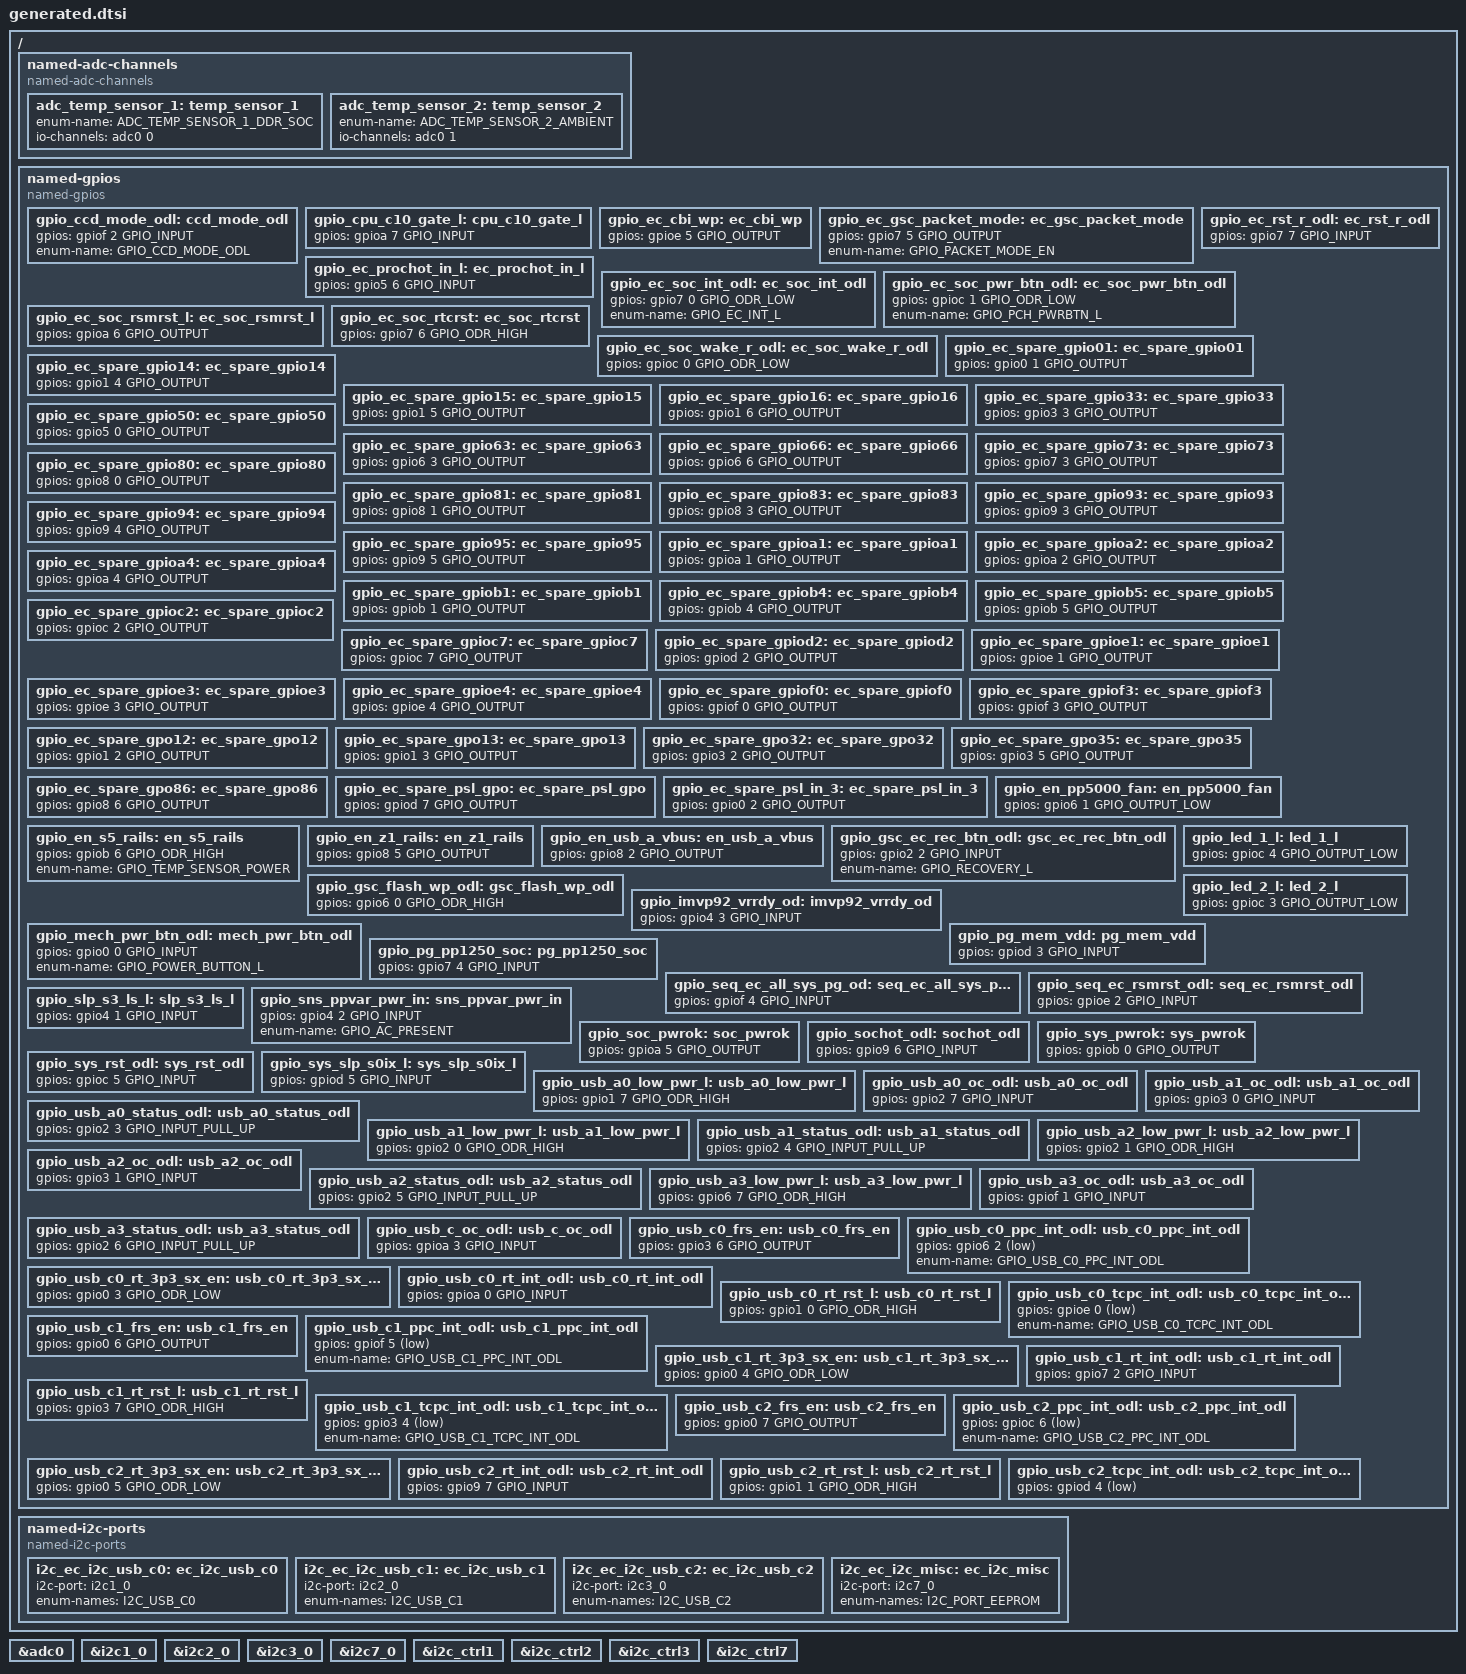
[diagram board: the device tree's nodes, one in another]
/* Copyright 2023 The ChromiumOS Authors
 * Use of this source code is governed by a BSD-style license that can be
 * found in the LICENSE file.
 *
 */

/ {

	named-adc-channels {
		compatible = "named-adc-channels";

		adc_temp_sensor_1: temp_sensor_1 {
			enum-name = "ADC_TEMP_SENSOR_1_DDR_SOC";
			io-channels = <&adc0 0>;
		};
		adc_temp_sensor_2: temp_sensor_2 {
			enum-name = "ADC_TEMP_SENSOR_2_AMBIENT";
			io-channels = <&adc0 1>;
		};
	};

	named-gpios {
		compatible = "named-gpios";

		gpio_ccd_mode_odl: ccd_mode_odl {
			gpios = <&gpiof 2 GPIO_INPUT>;
			enum-name = "GPIO_CCD_MODE_ODL";
		};
		gpio_cpu_c10_gate_l: cpu_c10_gate_l {
			gpios = <&gpioa 7 GPIO_INPUT>;
		};
		gpio_ec_cbi_wp: ec_cbi_wp {
			gpios = <&gpioe 5 GPIO_OUTPUT>;
		};
		gpio_ec_gsc_packet_mode: ec_gsc_packet_mode {
			gpios = <&gpio7 5 GPIO_OUTPUT>;
			enum-name = "GPIO_PACKET_MODE_EN";
		};
		gpio_ec_prochot_in_l: ec_prochot_in_l {
			gpios = <&gpio5 6 GPIO_INPUT>;
		};
		gpio_ec_rst_r_odl: ec_rst_r_odl {
			gpios = <&gpio7 7 GPIO_INPUT>;
		};
		gpio_ec_soc_int_odl: ec_soc_int_odl {
			gpios = <&gpio7 0 GPIO_ODR_LOW>;
			enum-name = "GPIO_EC_INT_L";
		};
		gpio_ec_soc_pwr_btn_odl: ec_soc_pwr_btn_odl {
			gpios = <&gpioc 1 GPIO_ODR_LOW>;
			enum-name = "GPIO_PCH_PWRBTN_L";
		};
		gpio_ec_soc_rsmrst_l: ec_soc_rsmrst_l {
			gpios = <&gpioa 6 GPIO_OUTPUT>;
		};
		gpio_ec_soc_rtcrst: ec_soc_rtcrst {
			gpios = <&gpio7 6 GPIO_ODR_HIGH>;
		};
		gpio_ec_soc_wake_r_odl: ec_soc_wake_r_odl {
			gpios = <&gpioc 0 GPIO_ODR_LOW>;
		};
		gpio_ec_spare_gpio01: ec_spare_gpio01 {
			gpios = <&gpio0 1 GPIO_OUTPUT>;
		};
		gpio_ec_spare_gpio14: ec_spare_gpio14 {
			gpios = <&gpio1 4 GPIO_OUTPUT>;
		};
		gpio_ec_spare_gpio15: ec_spare_gpio15 {
			gpios = <&gpio1 5 GPIO_OUTPUT>;
		};
		gpio_ec_spare_gpio16: ec_spare_gpio16 {
			gpios = <&gpio1 6 GPIO_OUTPUT>;
		};
		gpio_ec_spare_gpio33: ec_spare_gpio33 {
			gpios = <&gpio3 3 GPIO_OUTPUT>;
		};
		gpio_ec_spare_gpio50: ec_spare_gpio50 {
			gpios = <&gpio5 0 GPIO_OUTPUT>;
		};
		gpio_ec_spare_gpio63: ec_spare_gpio63 {
			gpios = <&gpio6 3 GPIO_OUTPUT>;
		};
		gpio_ec_spare_gpio66: ec_spare_gpio66 {
			gpios = <&gpio6 6 GPIO_OUTPUT>;
		};
		gpio_ec_spare_gpio73: ec_spare_gpio73 {
			gpios = <&gpio7 3 GPIO_OUTPUT>;
		};
		gpio_ec_spare_gpio80: ec_spare_gpio80 {
			gpios = <&gpio8 0 GPIO_OUTPUT>;
		};
		gpio_ec_spare_gpio81: ec_spare_gpio81 {
			gpios = <&gpio8 1 GPIO_OUTPUT>;
		};
		gpio_ec_spare_gpio83: ec_spare_gpio83 {
			gpios = <&gpio8 3 GPIO_OUTPUT>;
		};
		gpio_ec_spare_gpio93: ec_spare_gpio93 {
			gpios = <&gpio9 3 GPIO_OUTPUT>;
		};
		gpio_ec_spare_gpio94: ec_spare_gpio94 {
			gpios = <&gpio9 4 GPIO_OUTPUT>;
		};
		gpio_ec_spare_gpio95: ec_spare_gpio95 {
			gpios = <&gpio9 5 GPIO_OUTPUT>;
		};
		gpio_ec_spare_gpioa1: ec_spare_gpioa1 {
			gpios = <&gpioa 1 GPIO_OUTPUT>;
		};
		gpio_ec_spare_gpioa2: ec_spare_gpioa2 {
			gpios = <&gpioa 2 GPIO_OUTPUT>;
		};
		gpio_ec_spare_gpioa4: ec_spare_gpioa4 {
			gpios = <&gpioa 4 GPIO_OUTPUT>;
		};
		gpio_ec_spare_gpiob1: ec_spare_gpiob1 {
			gpios = <&gpiob 1 GPIO_OUTPUT>;
		};
		gpio_ec_spare_gpiob4: ec_spare_gpiob4 {
			gpios = <&gpiob 4 GPIO_OUTPUT>;
		};
		gpio_ec_spare_gpiob5: ec_spare_gpiob5 {
			gpios = <&gpiob 5 GPIO_OUTPUT>;
		};
		gpio_ec_spare_gpioc2: ec_spare_gpioc2 {
			gpios = <&gpioc 2 GPIO_OUTPUT>;
		};
		gpio_ec_spare_gpioc7: ec_spare_gpioc7 {
			gpios = <&gpioc 7 GPIO_OUTPUT>;
		};
		gpio_ec_spare_gpiod2: ec_spare_gpiod2 {
			gpios = <&gpiod 2 GPIO_OUTPUT>;
		};
		gpio_ec_spare_gpioe1: ec_spare_gpioe1 {
			gpios = <&gpioe 1 GPIO_OUTPUT>;
		};
		gpio_ec_spare_gpioe3: ec_spare_gpioe3 {
			gpios = <&gpioe 3 GPIO_OUTPUT>;
		};
		gpio_ec_spare_gpioe4: ec_spare_gpioe4 {
			gpios = <&gpioe 4 GPIO_OUTPUT>;
		};
		gpio_ec_spare_gpiof0: ec_spare_gpiof0 {
			gpios = <&gpiof 0 GPIO_OUTPUT>;
		};
		gpio_ec_spare_gpiof3: ec_spare_gpiof3 {
			gpios = <&gpiof 3 GPIO_OUTPUT>;
		};
		gpio_ec_spare_gpo12: ec_spare_gpo12 {
			gpios = <&gpio1 2 GPIO_OUTPUT>;
		};
		gpio_ec_spare_gpo13: ec_spare_gpo13 {
			gpios = <&gpio1 3 GPIO_OUTPUT>;
		};
		gpio_ec_spare_gpo32: ec_spare_gpo32 {
			gpios = <&gpio3 2 GPIO_OUTPUT>;
		};
		gpio_ec_spare_gpo35: ec_spare_gpo35 {
			gpios = <&gpio3 5 GPIO_OUTPUT>;
		};
		gpio_ec_spare_gpo86: ec_spare_gpo86 {
			gpios = <&gpio8 6 GPIO_OUTPUT>;
		};
		gpio_ec_spare_psl_gpo: ec_spare_psl_gpo {
			gpios = <&gpiod 7 GPIO_OUTPUT>;
		};
		gpio_ec_spare_psl_in_3: ec_spare_psl_in_3 {
			gpios = <&gpio0 2 GPIO_OUTPUT>;
		};
		gpio_en_pp5000_fan: en_pp5000_fan {
			gpios = <&gpio6 1 GPIO_OUTPUT_LOW>;
		};
		gpio_en_s5_rails: en_s5_rails {
			gpios = <&gpiob 6 GPIO_ODR_HIGH>;
			enum-name = "GPIO_TEMP_SENSOR_POWER";
		};
		gpio_en_z1_rails: en_z1_rails {
			gpios = <&gpio8 5 GPIO_OUTPUT>;
		};
		gpio_en_usb_a_vbus: en_usb_a_vbus {
			gpios = <&gpio8 2 GPIO_OUTPUT>;
		};
		gpio_gsc_ec_rec_btn_odl:  gsc_ec_rec_btn_odl {
			gpios = <&gpio2 2 GPIO_INPUT>;
			enum-name = "GPIO_RECOVERY_L";
		};
		gpio_gsc_flash_wp_odl: gsc_flash_wp_odl {
			gpios = <&gpio6 0 GPIO_ODR_HIGH>;
		};
		gpio_imvp92_vrrdy_od: imvp92_vrrdy_od {
			gpios = <&gpio4 3 GPIO_INPUT>;
		};
		gpio_led_1_l: led_1_l {
			gpios = <&gpioc 4 GPIO_OUTPUT_LOW>;
		};
		gpio_led_2_l: led_2_l {
			gpios = <&gpioc 3 GPIO_OUTPUT_LOW>;
		};
		gpio_mech_pwr_btn_odl: mech_pwr_btn_odl {
			gpios = <&gpio0 0 GPIO_INPUT>;
			enum-name = "GPIO_POWER_BUTTON_L";
		};
		gpio_pg_mem_vdd: pg_mem_vdd {
			gpios = <&gpiod 3 GPIO_INPUT>;
		};
		gpio_pg_pp1250_soc: pg_pp1250_soc {
			gpios = <&gpio7 4 GPIO_INPUT>;
		};
		gpio_seq_ec_all_sys_pg_od: seq_ec_all_sys_pg_od {
			gpios = <&gpiof 4 GPIO_INPUT>;
		};
		gpio_seq_ec_rsmrst_odl: seq_ec_rsmrst_odl {
			gpios = <&gpioe 2 GPIO_INPUT>;
		};
		gpio_slp_s3_ls_l: slp_s3_ls_l {
			gpios = <&gpio4 1 GPIO_INPUT>;
		};
		gpio_sns_ppvar_pwr_in: sns_ppvar_pwr_in {
			gpios = <&gpio4 2 GPIO_INPUT>;
			enum-name = "GPIO_AC_PRESENT";
		};
		gpio_soc_pwrok: soc_pwrok {
			gpios = <&gpioa 5 GPIO_OUTPUT>;
		};
		gpio_sochot_odl: sochot_odl {
			gpios = <&gpio9 6 GPIO_INPUT>;
		};
		gpio_sys_pwrok: sys_pwrok {
			gpios = <&gpiob 0 GPIO_OUTPUT>;
		};
		gpio_sys_rst_odl: sys_rst_odl {
			gpios = <&gpioc 5 GPIO_INPUT>;
		};
		gpio_sys_slp_s0ix_l: sys_slp_s0ix_l {
			gpios = <&gpiod 5 GPIO_INPUT>;
		};
		gpio_usb_a0_low_pwr_l: usb_a0_low_pwr_l {
			gpios = <&gpio1 7 GPIO_ODR_HIGH>;
		};
		gpio_usb_a0_oc_odl: usb_a0_oc_odl {
			gpios = <&gpio2 7 GPIO_INPUT>;
		};
		gpio_usb_a0_status_odl: usb_a0_status_odl {
			gpios = <&gpio2 3 GPIO_INPUT_PULL_UP>;
		};
		gpio_usb_a1_low_pwr_l: usb_a1_low_pwr_l {
			gpios = <&gpio2 0 GPIO_ODR_HIGH>;
		};
		gpio_usb_a1_oc_odl: usb_a1_oc_odl {
			gpios = <&gpio3 0 GPIO_INPUT>;
		};
		gpio_usb_a1_status_odl: usb_a1_status_odl {
			gpios = <&gpio2 4 GPIO_INPUT_PULL_UP>;
		};
		gpio_usb_a2_low_pwr_l: usb_a2_low_pwr_l {
			gpios = <&gpio2 1 GPIO_ODR_HIGH>;
		};
		gpio_usb_a2_oc_odl: usb_a2_oc_odl {
			gpios = <&gpio3 1 GPIO_INPUT>;
		};
		gpio_usb_a2_status_odl: usb_a2_status_odl {
			gpios = <&gpio2 5 GPIO_INPUT_PULL_UP>;
		};
		gpio_usb_a3_low_pwr_l: usb_a3_low_pwr_l {
			gpios = <&gpio6 7 GPIO_ODR_HIGH>;
		};
		gpio_usb_a3_oc_odl: usb_a3_oc_odl {
			gpios = <&gpiof 1 GPIO_INPUT>;
		};
		gpio_usb_a3_status_odl: usb_a3_status_odl {
			gpios = <&gpio2 6 GPIO_INPUT_PULL_UP>;
		};
		gpio_usb_c_oc_odl: usb_c_oc_odl {
			gpios = <&gpioa 3 GPIO_INPUT>;
		};
		gpio_usb_c0_frs_en: usb_c0_frs_en {
			gpios = <&gpio3 6 GPIO_OUTPUT>;
		};
		gpio_usb_c0_ppc_int_odl: usb_c0_ppc_int_odl {
			gpios = <&gpio6 2 (GPIO_INPUT | GPIO_ACTIVE_LOW)>;
			enum-name = "GPIO_USB_C0_PPC_INT_ODL";
		};
		gpio_usb_c0_rt_3p3_sx_en: usb_c0_rt_3p3_sx_en {
			gpios = <&gpio0 3 GPIO_ODR_LOW>;
		};
		gpio_usb_c0_rt_int_odl: usb_c0_rt_int_odl {
			gpios = <&gpioa 0 GPIO_INPUT>;
		};
		gpio_usb_c0_rt_rst_l: usb_c0_rt_rst_l {
			gpios = <&gpio1 0 GPIO_ODR_HIGH>;
		};
		gpio_usb_c0_tcpc_int_odl: usb_c0_tcpc_int_odl {
			gpios = <&gpioe 0 (GPIO_INPUT | GPIO_ACTIVE_LOW)>;
			enum-name = "GPIO_USB_C0_TCPC_INT_ODL";
		};
		gpio_usb_c1_frs_en: usb_c1_frs_en {
			gpios = <&gpio0 6 GPIO_OUTPUT>;
		};
		gpio_usb_c1_ppc_int_odl: usb_c1_ppc_int_odl {
			gpios = <&gpiof 5 (GPIO_INPUT| GPIO_ACTIVE_LOW) >;
			enum-name = "GPIO_USB_C1_PPC_INT_ODL";
		};
		gpio_usb_c1_rt_3p3_sx_en: usb_c1_rt_3p3_sx_en {
			gpios = <&gpio0 4 GPIO_ODR_LOW>;
		};
		gpio_usb_c1_rt_int_odl: usb_c1_rt_int_odl {
			gpios = <&gpio7 2 GPIO_INPUT>;
		};
		gpio_usb_c1_rt_rst_l: usb_c1_rt_rst_l {
			gpios = <&gpio3 7 GPIO_ODR_HIGH>;
		};
		gpio_usb_c1_tcpc_int_odl: usb_c1_tcpc_int_odl {
			gpios = <&gpio3 4 (GPIO_INPUT | GPIO_ACTIVE_LOW)>;
			enum-name = "GPIO_USB_C1_TCPC_INT_ODL";
		};
		gpio_usb_c2_frs_en: usb_c2_frs_en {
			gpios = <&gpio0 7 GPIO_OUTPUT>;
		};
		gpio_usb_c2_ppc_int_odl: usb_c2_ppc_int_odl {
			gpios = <&gpioc 6 (GPIO_INPUT | GPIO_ACTIVE_LOW)>;
			enum-name = "GPIO_USB_C2_PPC_INT_ODL";
		};
		gpio_usb_c2_rt_3p3_sx_en: usb_c2_rt_3p3_sx_en {
			gpios = <&gpio0 5 GPIO_ODR_LOW>;
		};
		gpio_usb_c2_rt_int_odl: usb_c2_rt_int_odl {
			gpios = <&gpio9 7 GPIO_INPUT>;
		};
		gpio_usb_c2_rt_rst_l: usb_c2_rt_rst_l {
			gpios = <&gpio1 1 GPIO_ODR_HIGH>;
		};
		gpio_usb_c2_tcpc_int_odl: usb_c2_tcpc_int_odl {
			gpios = <&gpiod 4 (GPIO_INPUT | GPIO_ACTIVE_LOW)>;
		};
	};

	named-i2c-ports {
		compatible = "named-i2c-ports";

		i2c_ec_i2c_usb_c0: ec_i2c_usb_c0 {
			i2c-port = <&i2c1_0>;
			enum-names = "I2C_USB_C0";
		};
		i2c_ec_i2c_usb_c1: ec_i2c_usb_c1 {
			i2c-port = <&i2c2_0>;
			enum-names = "I2C_USB_C1";
		};
		i2c_ec_i2c_usb_c2: ec_i2c_usb_c2 {
			i2c-port = <&i2c3_0>;
			enum-names = "I2C_USB_C2";
		};
		i2c_ec_i2c_misc: ec_i2c_misc {
			i2c-port = <&i2c7_0>;
			enum-names = "I2C_PORT_EEPROM";
		};
	};
};

&adc0 {
	status = "okay";
};

&i2c1_0 {
	status = "okay";
};

&i2c2_0 {
	status = "okay";
};

&i2c3_0 {
	status = "okay";
};

&i2c7_0 {
	status = "okay";
};

&i2c_ctrl1 {
	status = "okay";
};

&i2c_ctrl2 {
	status = "okay";
};

&i2c_ctrl3 {
	status = "okay";
};

&i2c_ctrl7 {
	status = "okay";
};
